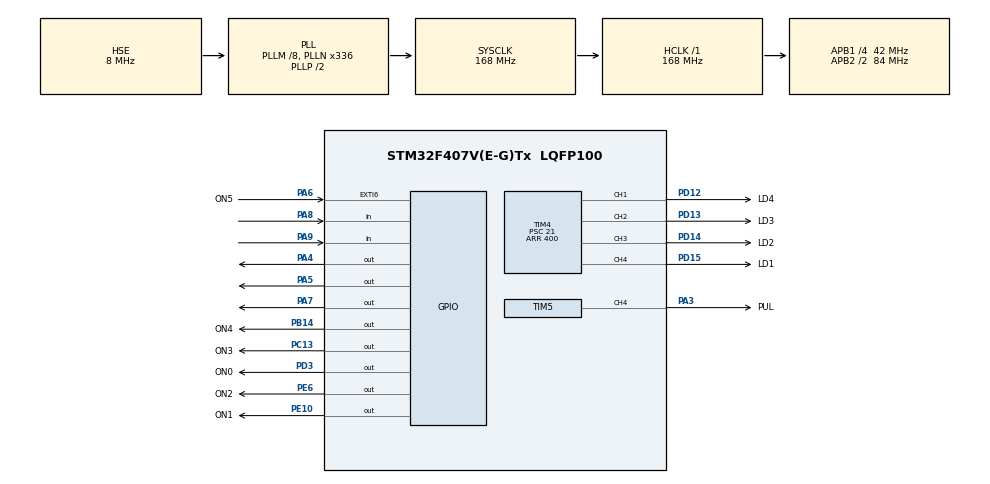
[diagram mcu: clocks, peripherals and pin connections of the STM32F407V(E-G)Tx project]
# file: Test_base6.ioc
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Mcu.Family=STM32F4
Mcu.Name=STM32F407V(E-G)Tx
Mcu.Package=LQFP100
NVIC.PriorityGroup=NVIC_PRIORITYGROUP_4
PA0-WKUP.Signal=S_TIM5_CH1
PA1.Signal=S_TIM5_CH2
PA13.Mode=Serial_Wire
PA13.Signal=SYS_JTMS-SWDIO
PA14.Mode=Serial_Wire
PA14.Signal=SYS_JTCK-SWCLK
PA2.Signal=S_TIM5_CH3
PA3.GPIO_Label=PUL
PA3.GPIO_ModeDefaultPP=GPIO_MODE_AF_PP
PA3.GPIO_PuPd=GPIO_NOPULL
PA3.GPIO_Speed=GPIO_SPEED_FREQ_VERY_HIGH
PA3.Signal=S_TIM5_CH4
PA4.GPIO_ModeDefaultOutputPP=GPIO_MODE_OUTPUT_PP
PA4.GPIO_PuPd=GPIO_NOPULL
PA4.GPIO_Speed=GPIO_SPEED_FREQ_LOW
PA4.PinState=GPIO_PIN_RESET
PA4.Signal=GPIO_Output
PA5.GPIO_ModeDefaultOutputPP=GPIO_MODE_OUTPUT_PP
PA5.GPIO_PuPd=GPIO_NOPULL
PA5.GPIO_Speed=GPIO_SPEED_FREQ_LOW
PA5.PinState=GPIO_PIN_RESET
PA5.Signal=GPIO_Output
PA6.GPIO_Label=ON5
PA6.Signal=GPXTI6
PA7.GPIO_ModeDefaultOutputPP=GPIO_MODE_OUTPUT_PP
PA7.GPIO_PuPd=GPIO_NOPULL
PA7.GPIO_Speed=GPIO_SPEED_FREQ_LOW
PA7.PinState=GPIO_PIN_RESET
PA7.Signal=GPIO_Output
PA8.GPIO_Mode=GPIO_MODE_INPUT
PA8.GPIO_PuPd=GPIO_NOPULL
PA8.Signal=GPIO_Input
PA9.GPIO_Mode=GPIO_MODE_INPUT
PA9.GPIO_PuPd=GPIO_NOPULL
PA9.Signal=GPIO_Input
PB14.GPIO_Label=ON4
PB14.Signal=GPIO_Output
PC13-ANTI_TAMP.GPIO_Label=ON3
PC13-ANTI_TAMP.PinState=GPIO_PIN_RESET
PC13-ANTI_TAMP.Signal=GPIO_Output
PD12.GPIO_Label=LD4
PD12.GPIO_ModeDefaultPP=GPIO_MODE_AF_PP
PD12.GPIO_PuPd=GPIO_NOPULL
PD12.GPIO_Speed=GPIO_SPEED_FREQ_VERY_HIGH
PD12.Signal=S_TIM4_CH1
PD13.GPIO_Label=LD3
PD13.GPIO_ModeDefaultPP=GPIO_MODE_AF_PP
PD13.GPIO_PuPd=GPIO_NOPULL
PD13.GPIO_Speed=GPIO_SPEED_FREQ_VERY_HIGH
PD13.Signal=S_TIM4_CH2
PD14.GPIO_Label=LD2
PD14.GPIO_ModeDefaultPP=GPIO_MODE_AF_PP
PD14.GPIO_PuPd=GPIO_NOPULL
PD14.GPIO_Speed=GPIO_SPEED_FREQ_VERY_HIGH
PD14.Signal=S_TIM4_CH3
PD15.GPIO_Label=LD1
PD15.GPIO_ModeDefaultPP=GPIO_MODE_AF_PP
PD15.GPIO_PuPd=GPIO_NOPULL
PD15.GPIO_Speed=GPIO_SPEED_FREQ_VERY_HIGH
PD15.Signal=S_TIM4_CH4
PD3.GPIO_Label=ON0
PD3.PinState=GPIO_PIN_RESET
PD3.Signal=GPIO_Output
PE10.GPIO_Label=ON1
PE10.PinState=GPIO_PIN_RESET
PE10.Signal=GPIO_Output
PE6.GPIO_Label=ON2
PE6.PinState=GPIO_PIN_RESET
PE6.Signal=GPIO_Output
PH0-OSC_IN.Mode=HSE-External-Oscillator
PH0-OSC_IN.Signal=RCC_OSC_IN
PH1-OSC_OUT.Mode=HSE-External-Oscillator
PH1-OSC_OUT.Signal=RCC_OSC_OUT
ProjectManager.HeapSize=0x200
ProjectManager.StackSize=0x400
ProjectManager.TargetToolchain=MDK-ARM V5.27
RCC.48MHZClocksFreq_Value=84000000
RCC.AHBFreq_Value=168000000
RCC.APB1CLKDivider=RCC_HCLK_DIV4
RCC.APB1Freq_Value=42000000
RCC.APB1TimFreq_Value=84000000
RCC.APB2CLKDivider=RCC_HCLK_DIV2
RCC.APB2Freq_Value=84000000
RCC.APB2TimFreq_Value=168000000
RCC.CortexFreq_Value=168000000
RCC.HCLKFreq_Value=168000000
RCC.HSE_VALUE=8000000
RCC.HSI_VALUE=16000000
RCC.LSE_VALUE=32768
RCC.PLLM=8
RCC.PLLN=336
RCC.PLLSourceVirtual=RCC_PLLSOURCE_HSE
RCC.RCC_RTC_Clock_Source=RCC_RTCCLKSOURCE_LSI
RCC.RCC_RTC_Clock_SourceVirtual=RCC_RTCCLKSOURCE_LSI
RCC.SYSCLKFreq_VALUE=168000000
RCC.SYSCLKSource=RCC_SYSCLKSOURCE_PLLCLK
RCC.VCOOutputFreq_Value=336000000
SH.S_TIM4_CH1.0=TIM4_CH1,PWM Generation1 CH1
SH.S_TIM4_CH2.0=TIM4_CH2,PWM Generation2 CH2
SH.S_TIM4_CH3.0=TIM4_CH3,PWM Generation3 CH3
SH.S_TIM4_CH4.0=TIM4_CH4,PWM Generation4 CH4
SH.S_TIM5_CH1.0=TIM5_CH1
SH.S_TIM5_CH2.0=TIM5_CH2
SH.S_TIM5_CH3.0=TIM5_CH3
SH.S_TIM5_CH4.0=TIM5_CH4,PWM Generation4 CH4
TIM4.Channel-PWM\ Generation1\ CH1=TIM_CHANNEL_1
TIM4.Channel-PWM\ Generation2\ CH2=TIM_CHANNEL_2
TIM4.Channel-PWM\ Generation3\ CH3=TIM_CHANNEL_3
TIM4.Channel-PWM\ Generation4\ CH4=TIM_CHANNEL_4
TIM4.Period=400
TIM4.Prescaler=21
TIM5.Channel-PWM\ Generation4\ CH4=TIM_CHANNEL_4
TIM5.Period=400
TIM5.Prescaler=21
VP_TIM4_VS_ClockSourceINT.Mode=Internal
VP_TIM5_VS_ClockSourceINT.Mode=Internal
board=custom

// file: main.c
/* USER CODE BEGIN Header */
/**
  ******************************************************************************
  * @file           : main.c
  * @brief          : Main program body
  ******************************************************************************
  * @attention
  *
  * <h2><center>&copy; Copyright (c) 2020 STMicroelectronics.
  * All rights reserved.</center></h2>
  *
  * This software component is licensed by ST under BSD 3-Clause license,
  * the "License"; You may not use this file except in compliance with the
  * License. You may obtain a copy of the License at:
  *                        opensource.org/licenses/BSD-3-Clause
  *
  ******************************************************************************
  */
/* USER CODE END Header */

#include "main.h"
#include "tim.h"
#include "gpio.h"

/* USER CODE BEGIN PTD */
#define PWMfreq 10000
/* USER CODE END PTD */

/* USER CODE BEGIN PV */
uint16_t pwm=0;
uint16_t step =0;
uint8_t tx_buff[]={"robotics adt"};
uint8_t RecvBuffer[8];
/* USER CODE END PV */

void SystemClock_Config(void);
/* USER CODE BEGIN PFP */
void HAL_UART_RxCpltCallback(UART_HandleTypeDef *huart);
void HAL_UART_TxCpltCallback(UART_HandleTypeDef *huart);
void PWM_out(uint32_t freq, int16_t duty, TIM_HandleTypeDef *htim, uint32_t Channel);

/* USER CODE END PFP */

/* USER CODE BEGIN 0 */
/*void PWM_LED()
{
		for(pwm =0;pwm<400;pwm=pwm+4)
		{
			__HAL_TIM_SET_COMPARE(&htim4,TIM_CHANNEL_1,pwm);
			__HAL_TIM_SET_COMPARE(&htim4,TIM_CHANNEL_2,pwm);
			__HAL_TIM_SET_COMPARE(&htim4,TIM_CHANNEL_3,pwm);
			__HAL_TIM_SET_COMPARE(&htim4,TIM_CHANNEL_4,pwm);
			__HAL_TIM_SET_COMPARE(&htim5,TIM_CHANNEL_4,pwm);
			HAL_Delay(50);
		}
		HAL_Delay(2000);
		for(pwm =400;pwm>0;pwm=pwm-4)
		{
			__HAL_TIM_SET_COMPARE(&htim4,TIM_CHANNEL_1,pwm);
			__HAL_TIM_SET_COMPARE(&htim4,TIM_CHANNEL_2,pwm);
			__HAL_TIM_SET_COMPARE(&htim4,TIM_CHANNEL_3,pwm);
			__HAL_TIM_SET_COMPARE(&htim4,TIM_CHANNEL_4,pwm);
			__HAL_TIM_SET_COMPARE(&htim5,TIM_CHANNEL_4,pwm);
			HAL_Delay(50);
		}
		HAL_Delay(2000);
}*/

/* USER CODE END 0 */

int main(void)
{

  /* MCU Configuration--------------------------------------------------------*/

  /* Reset of all peripherals, Initializes the Flash interface and the Systick. */
  HAL_Init();

  /* Configure the system clock */
  SystemClock_Config();

  /* Initialize all configured peripherals */
  MX_GPIO_Init();
  MX_TIM5_Init();
  MX_TIM4_Init();
  /* USER CODE BEGIN 2 */
	HAL_UART_Receive_IT(&huart3,RecvBuffer,8);
	HAL_UART_Transmit_IT(&huart3,tx_buff,12);
	HAL_TIM_PWM_Start(&htim5,TIM_CHANNEL_4);
  /* USER CODE END 2 */
		HAL_GPIO_WritePin(ON0_GPIO_Port,ON0_Pin,GPIO_PIN_SET);
		HAL_GPIO_WritePin(ON1_GPIO_Port,ON1_Pin,GPIO_PIN_SET);
		HAL_GPIO_WritePin(ON2_GPIO_Port,ON2_Pin,GPIO_PIN_SET);
		HAL_GPIO_WritePin(ON3_GPIO_Port,ON3_Pin,GPIO_PIN_SET);
		HAL_GPIO_WritePin(ON4_GPIO_Port,ON4_Pin,GPIO_PIN_SET);
		HAL_GPIO_WritePin(ON5_GPIO_Port,ON5_Pin,GPIO_PIN_SET);
	PWM_out(PWMfreq,1000,&htim5,4);
	HAL_Delay(2000);
	PWM_out(PWMfreq,0,&htim5,4);
	HAL_Delay(2000);

  /* Infinite loop */
  while (1)
  {

  }
}

void HAL_UART_RxCpltCallback(UART_HandleTypeDef *huart){
		if(huart->Instance==huart3.Instance)
		{
			HAL_UART_Receive_IT(&huart3,RecvBuffer,8);
		}

}
void HAL_UART_TxCpltCallback(UART_HandleTypeDef *huart){
		__NOP();
}
void PWM_out(uint32_t freq, int16_t duty, TIM_HandleTypeDef *htim, uint32_t Channel)
{
	uint32_t period;
	period = 84000000/(freq*(htim->Instance->PSC+1))-1;
	if (period > 0xffff)
		period = 0xffff;

	htim->Instance->ARR = period;
	if (duty<-1000)
		duty = -1000;
	else if (duty > 1000)
		duty = 1000;

 if (duty > 0)	{
		HAL_GPIO_WritePin(SIGN_GPIO_Port, SIGN_Pin, GPIO_PIN_SET); // dir = 1
	}
	else 	{
		HAL_GPIO_WritePin(SIGN_GPIO_Port, SIGN_Pin, GPIO_PIN_RESET); // dir = 0
		duty = -duty;
	}

	duty = (htim->Instance->ARR+1)*duty/1000;
	switch(Channel){
		case 1:
			htim->Instance->CCR1 = (uint32_t)duty;
		break;
		case 2:
			htim->Instance->CCR2 = (uint32_t)duty;
		break;
		case 3:
			htim->Instance->CCR3 = (uint32_t)duty;
		break;
		case 4:
			htim->Instance->CCR4 = (uint32_t)duty;
		break;
		default:
		break;
	}
}
void SystemClock_Config(void)
{
  RCC_OscInitTypeDef RCC_OscInitStruct = {0};
  RCC_ClkInitTypeDef RCC_ClkInitStruct = {0};

  /** Configure the main internal regulator output voltage
  */
  __HAL_RCC_PWR_CLK_ENABLE();
  __HAL_PWR_VOLTAGESCALING_CONFIG(PWR_REGULATOR_VOLTAGE_SCALE1);
  /** Initializes the CPU, AHB and APB busses clocks
  */
  RCC_OscInitStruct.OscillatorType = RCC_OSCILLATORTYPE_HSE;
  RCC_OscInitStruct.HSEState = RCC_HSE_ON;
  RCC_OscInitStruct.PLL.PLLState = RCC_PLL_ON;
  RCC_OscInitStruct.PLL.PLLSource = RCC_PLLSOURCE_HSE;
  RCC_OscInitStruct.PLL.PLLM = 8;
  RCC_OscInitStruct.PLL.PLLN = 336;
  RCC_OscInitStruct.PLL.PLLP = RCC_PLLP_DIV2;
  RCC_OscInitStruct.PLL.PLLQ = 4;
  if (HAL_RCC_OscConfig(&RCC_OscInitStruct) != HAL_OK)
  {
    Error_Handler();
  }
  /** Initializes the CPU, AHB and APB busses clocks
  */
  RCC_ClkInitStruct.ClockType = RCC_CLOCKTYPE_HCLK|RCC_CLOCKTYPE_SYSCLK
                              |RCC_CLOCKTYPE_PCLK1|RCC_CLOCKTYPE_PCLK2;
  RCC_ClkInitStruct.SYSCLKSource = RCC_SYSCLKSOURCE_PLLCLK;
  RCC_ClkInitStruct.AHBCLKDivider = RCC_SYSCLK_DIV1;
  RCC_ClkInitStruct.APB1CLKDivider = RCC_HCLK_DIV4;
  RCC_ClkInitStruct.APB2CLKDivider = RCC_HCLK_DIV2;

  if (HAL_RCC_ClockConfig(&RCC_ClkInitStruct, FLASH_LATENCY_5) != HAL_OK)
  {
    Error_Handler();
  }
}

void Error_Handler(void)
{
}

/************************ (C) COPYRIGHT STMicroelectronics *****END OF FILE****/
